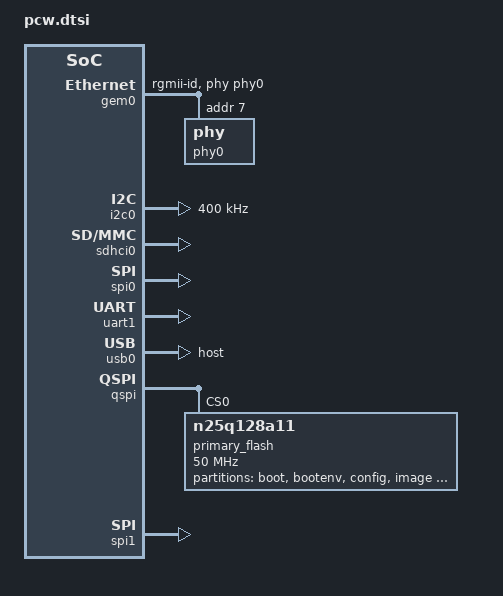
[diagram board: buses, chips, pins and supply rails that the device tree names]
/*
 * CAUTION: This file is automatically generated by Xilinx.
 * Version: HSI 
 * Today is: Mon Apr  4 15:16:26 2022
 */

/ {
	interrupt-parent = <&intc>;
	
	cpus {
		cpu@0 {
			operating-points = <666666 1000000 333333 1000000>;
		};
	};
	
};

&gem0 {
	enet-reset = <&gpio0 47 0>;
	phy-mode = "rgmii-id";
	status = "okay";
	xlnx,ptp-enet-clock = <0x69f6bcb>;
	phy-handle = <&phy0>;
	pinctrl-names = "default";

	phy0: phy@7 {
		device_type = "ethernet-phy";
		reg = <0x7>;
	};
};
&gpio0 {
	emio-gpio-width = <64>;
	gpio-mask-high = <0x0>;
	gpio-mask-low = <0x5600>;
};
&i2c0 {
	clock-frequency = <400000>;
	i2c-reset = <&gpio0 46 0>;
	status = "okay";
};
&intc {
	num_cpus = <2>;
	num_interrupts = <96>;
};
&sdhci0 {
	status = "okay";
	xlnx,has-cd = <0x1>;
	xlnx,has-power = <0x0>;
	xlnx,has-wp = <0x1>;
};
&spi0 {
	is-decoded-cs = <0>;
	num-cs = <3>;
	status = "okay";
};
&uart1 {
	device_type = "serial";
	port-number = <0>;
	status = "okay";
};
&usb0 {
	phy_type = "ulpi";
	status = "okay";
	usb-reset = <&gpio0 7 0>;
	dr_mode = "host";           /* This breaks OTG mode */
	xlnx,phy-reset-gpio = <&gpio0 7 0>;
};
&clkc {
	fclk-enable = <0x3>;
	ps-clk-frequency = <33333333>;
};
&qspi {
	status = "okay";
	is-dual = <1>;
	num-cs = <1>;
	spi-rx-bus-width = <8>;
	spi-tx-bus-width = <8>;
	
	primary_flash: ps7-qspi@0 {
		#address-cells = <1>;
		#size-cells = <1>;
		spi-tx-bus-width = <1>;
		spi-rx-bus-width = <4>;
		compatible = "n25q128a11";
		reg = <0x0>;
		spi-max-frequency = <50000000>;
		partition@0 {
			label = "boot";
			reg = <0x00000000 0x00500000>;
		};
		partition@500000 {
			label = "bootenv";
			reg = <0x00500000 0x00020000>;
		};
		partition@520000 {
			label = "config";
			reg = <0x00520000 0x00020000>;
		};
		partition@540000 {
			label = "image";
			reg = <0x00540000 0x00a80000>;
		};
		partition@fc0000 {
			label = "spare";
			reg = <0x00fc0000 0x00000000>;
		};
	};
};


&watchdog0 {
	reset-on-timeout;
};
&spi1 {
	status = "okay";
};
